# NUC505_v1 register map
File version: 1.0
Registers are 32-bit, read-write, reset 0x0 unless marked. A register's access mark holds for its fields unless they carry their own. Offsets are from the block's base; [hi:lo] are bit positions; {n}, {i} and the like mark numbered series; 'fields as' and 'values as' point back to an identical list.

## PWM — PWM Register Map
Base 0x400E6000
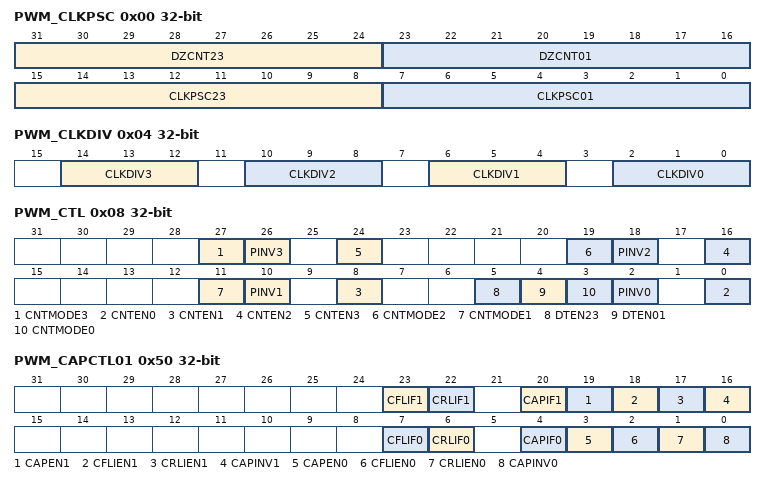
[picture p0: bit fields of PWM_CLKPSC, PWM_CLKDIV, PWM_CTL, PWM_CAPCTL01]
0x00 PWM_CLKPSC — PWM Pre-scale Register
  [31:24] DZCNT23 — Dead-time Interval Register 1. These 8-bit determine Dead-time length.
  [23:16] DZCNT01 — Dead-time Interval Register 0. These 8-bit determine Dead-time length.
  [15:8] CLKPSC23 — Clock Pre-scale 1 for PWM Counter 2 3. Clock input is divided by (CLKPSC23+1) before it is fed to the counter 2 3.
  [7:0] CLKPSC01 — Clock Pre-scale 0 for PWM Counter 0 1. Clock input is divided by (CLKPSC01+1) before it is fed to the counter 0 1.
0x04 PWM_CLKDIV — PWM Clock Select Register
  [14:12] CLKDIV3 — PWM Counter 3 Clock Source Selection. Select clock input for timer 3.
    0=PWM_CLK/2; 1=PWM_CLK/4; 2=PWM_CLK/8; 3=PWM_CLK/16; 4=PWM_CLK/1
  [10:8] CLKDIV2 — PWM Counter 2 Clock Source Selection. Select clock input for PWM Counter 2. (Table is the same as CLKDIV3)
  [6:4] CLKDIV1 — PWM Counter 1 Clock Source Selection. Select clock input for PWM Counter 1. (Table is the same as CLKDIV3)
  [2:0] CLKDIV0 — PWM Counter 0 Clock Source Selection. Select clock input for PWM Counter 0. (Table is the same as CLKDIV3)
0x08 PWM_CTL — PWM Control Register
  [27] CNTMODE3 — PWM Counter 3 Auto-reload Mode/One-shot Mode. Note: If there is a rising transition at this bit, it will cause PWM_PERIOD3 and PWM_CMPDAT3 be cleared.
    0=One-Shot mode; 1=Auto-Reload mode
  [8n+2] PINV{n} (n=0..3) — PWM Counter {n} Inverter ON/OFF
    0=Inverter OFF; 1=Inverter ON
  [8n] CNTEN{n} (n=0..3) — PWM Counter {n} Enable Control
    0=PWM Counter and clock prescaler stops running; 1=PWM Counter and clock prescaler starts running
  [19] CNTMODE2 — PWM Counter 2 Auto-reload Mode/One-shot Mode. Note: If there is a rising transition at this bit, it will cause PWM_PERIOD2 and PWM_CMPDAT2 be cleared.
    0=One-shot mode; 1=Auto-reload mode
  [11] CNTMODE1 — PWM Counter 1 Auto-reload Mode/One-shot Mode. Note: If there is a rising transition at this bit, it will cause PWM_PERIOD1 and PWM_CMPDAT1 be cleared.
    0=One-shot mode; 1=Auto-reload mode
  [5] DTEN23 — Dead-time 1 Generator Enable Control
    0=Dead-time generator stops running; 1=Dead-time generator starts running
  [4] DTEN01 — Dead-time 0 Generator Enable Control
    values as DTEN23
  [3] CNTMODE0 — PWM Counter 0 Auto-reload Mode/One-shot Mode. If there is a rising transition at this bit, it will cause PWM_PERIOD0 and PWM_CMPDAT0 be cleared.
    0=One-shot mode; 1=Auto-reload mode
{0xC+0xC*i} PWM_PERIOD{i} (i=0..3) — PWM Period Register {i}
  [15:0] PERIOD — PWM Period Register. PERIOD determines the PWM period. Note: Any write to PERIOD will take effect in the next PWM cycle.
{0x10+0xC*i} PWM_CMPDAT{i} (i=0..3) — PWM Comparator Register {i}
  [15:0] CMP — PWM Compare Register. CMP determines the PWM output duty ratio. Note: Any write to CMP will take effect in the next PWM cycle.
{0x14+0xC*i} PWM_CNT{i} ro (i=0..3) — PWM Data Register {i}
  [15:0] CNT — PWM Data Register. User can monitor CNT to know current value in 16-bit down counter.
0x40 PWM_INTEN — PWM Interrupt Enable Register
  [3:0] PIEN — PWM Period Interrupt Enable Control. Note: Each bit controls the corresponding PWM channel.
    0=Period interrupt Disabled; 1=Period interrupt Enabled
0x44 PWM_INTSTS — PWM Interrupt Indication Register
  [3:0] PIF — PWM Timer Interrupt Flag. Note1: Each bit controls the corresponding PWM channel. Note2: User can clear each interrupt flag by writing a one to corresponding bit
    0=Interrupt Flag OFF; 1=Interrupt Flag ON
0x50 PWM_CAPCTL01 — Capture Control Register 0
  [23] CFLIF1 — Capture Falling Latch Interrupt Flag. Note: This bit must be cleared by writing 1 to it.
    0=No capture falling latch condition happened; 1=Capture falling latch condition happened, and this flag will be set to high
  [22] CRLIF1 — Capture Rising Latch Interrupt Flag. Note: This bit must be cleared by writing 1 to it.
    0=No capture rising latch condition happened; 1=Capture rising latch condition happened, and this flag will be set to high
  [20] CAPIF1 — Capture 1 Interrupt Indication. Note: If this bit is "1", PWM-counter 1 will not reload when the next capture interrupt occurs. Write "1" to clear.
    0=Interrupt Flag OFF; 1=Interrupt Flag ON
  [19] CAPEN1 — Capture Channel 1 Function Enable Control. Note1: When Enabled, Capture latched the PMW-counter 1 and saved to PWM_RCAPDAT1 (Rising latch) and PWM_FCAPDAT1 (Falling latch). Note2: When Disabled, Capture does not update PWM_RCAPDAT1 and PWM_FCAPDAT1, and disable Channel 1 Interrupt.
    0=Capture function Disabled; 1=Capture function Enabled
  [18] CFLIEN1 — Channel1 Falling Interrupt Enable Control. Note: When Enabled, if Capture detects Channel 1 has falling transition, Capture issues an Interrupt.
    0=Channel1 Falling Interrupt Disabled; 1=Channel1 Falling Interrupt Enabled
  [17] CRLIEN1 — Channel 1 Rising Interrupt Enable Control. Note: When Enabled, if Capture detects Channel 1 has rising transition, Capture issues an Interrupt.
    0=Channel 1 Rising Interrupt Disabled; 1=Channel 1 Rising Interrupt Enabled
  [16] CAPINV1 — Capture 1 Inverter Enable Control
    0=Capture source inverter Disabled; 1=Capture source inverter Enabled
  [7] CFLIF0 — Capture Falling Latch Interrupt Flag. Note: This bit must be cleared by writing 1 to it.
    values as CFLIF1
  [6] CRLIF0 — Capture Rising Latch Interrupt Flag. Note: This bit must be cleared by writing 1 to it.
    values as CRLIF1
  [4] CAPIF0 — Capture 0 Interrupt Indication. Note: If this bit is "1", PWM-counter 0 will not reload when the next capture interrupt occur. Write "1" clear.
    0=Interrupt Flag OFF; 1=Interrupt Flag ON
  [3] CAPEN0 — Capture Channel 0 Function Enable Control. Note1: When Enabled, Capture latched the PWM-counter value and saved to PWM_RCAPDAT0 (Rising latch) and PWM_FCAPDAT0 (Falling latch). Note2: When Disabled, Capture does not update PWM_RCAPDAT0 and PWM_FCAPDAT0, and disable Channel 0 Interrupt.
    0=Capture function Disabled; 1=Capture function Enabled
  [2] CFLIEN0 — Channel 0 Falling Interrupt Enable Control. Note: When Enabled, if Capture detects Channel 0 has falling transition, Capture issues an Interrupt.
    0=Channel 0 Falling Interrupt Disabled; 1=Channel 0 Falling Interrupt Enabled
  [1] CRLIEN0 — Channel 0 Rising Interrupt Enable Control. Note: When Enabled, if Capture detects Channel 0 has rising transition, Capture issues an Interrupt.
    0=Channel 0 Rising Interrupt Enable Disabled; 1=Channel 0 Rising Interrupt Enable Enabled
  [0] CAPINV0 — Capture 0 Inverter Enable Control
    0=Capture source inverter Disabled; 1=Capture source inverter Enabled. Reverse the input signal from GPIO
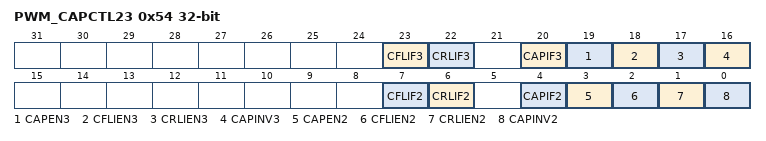
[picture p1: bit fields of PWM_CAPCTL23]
0x54 PWM_CAPCTL23 — Capture Control Register 1
  [23] CFLIF3 — Capture Falling Latch Interrupt Flag. Note: This bit must be cleared by writing 1 to it.
    0=No capture falling latch condition happened; 1=Capture falling latch condition happened, this flag will be set to high
  [22] CRLIF3 — Capture Rising Latch Interrupt Flag. Note: This bit must be cleared by writing 1 to it.
    0=No capture rising latch condition happened; 1=Capture rising latch condition happened, this flag will be set to high
  [20] CAPIF3 — Capture 3 Interrupt Indication. Note: If this bit is "1", PWM-counter 3 will not reload when next capture interrupt occur.
    0=Interrupt Flag OFF; 1=Interrupt Flag ON
  [19] CAPEN3 — Capture Channel 3 Function Enable Control. Note: When Enabled, Capture latched the PMW-counter and saved to PWM_RCAPDAT3 (Rising latch) and PWM_FCAPDAT3 (Falling latch). When Disabled, Capture does not update PWM_RCAPDAT3 and PWM_FCAPDAT3, and disable Channel 3 Interrupt.
    0=Capture function Disabled; 1=Capture function Enabled
  [18] CFLIEN3 — Channel 3 Falling Interrupt Enable Control. Note: When Enabled, if Capture detects Channel 3 has falling transition, Capture issues an Interrupt.
    0=Channel 3 Falling Interrupt Disabled; 1=Channel 3 Falling Interrupt Enabled
  [17] CRLIEN3 — Channel 3 Rising Interrupt Enable Control. Note: When Enabled, if Capture detects Channel 3 has rising transition, Capture issues an Interrupt.
    0=Channel 3 Rising Interrupt Disabled; 1=Channel 3 Rising Interrupt Enabled
  [16] CAPINV3 — Capture 3 Inverter Enable Control
    values as PWM_CAPCTL01.CAPINV0
  [7] CFLIF2 — Capture Falling Latch Interrupt Flag. Note: This bit must be cleared by writing 1 to it.
    values as CFLIF3
  [6] CRLIF2 — Capture Rising Latch Interrupt Flag. Note: This bit must be cleared by writing 1 to it.
    values as CRLIF3
  [4] CAPIF2 — Capture 2 Interrupt Indication. Note: If this bit is "1", PWM-counter 2 will not reload when next capture interrupt occur.
    0=Interrupt Flag OFF; 1=Interrupt Flag ON
  [3] CAPEN2 — Capture Channel 2 Function Enable Control. Note: When Enabled, Capture latched the PMW-counter value and saved to PWM_RCAPDAT2 (Rising latch) and PWM_FCAPDAT2 (Falling latch). When Disabled, Capture does not update PWM_RCAPDAT2 and PWM_FCAPDAT2, and disable Channel 2 Interrupt.
    0=Capture function Disabled; 1=Capture function Enabled
  [2] CFLIEN2 — Channel 2 Falling Interrupt Enable Control. Note: When Enabled, if Capture detects Channel 2 has falling transition, Capture issues an Interrupt.
    0=Channel 2 Falling Interrupt Disabled; 1=Channel 2 Falling Interrupt Enabled
  [1] CRLIEN2 — Channel 2 Rising Interrupt Enable Control. Note: When Enabled, if Capture detects Channel 2 has rising transition, Capture issues an Interrupt.
    0=Channel 2 Rising Interrupt Disabled; 1=Channel 2 Rising Interrupt Enabled
  [0] CAPINV2 — Capture 2 Inverter Enable Control
    values as PWM_CAPCTL01.CAPINV0
{0x58+8i} PWM_RCAPDAT{i} (i=0..3) — Capture Rising Latch Register (Channel {i})
  [15:0] RCAPDAT — Capture Rising Latch Register. Latch the PWM counter when Channel 0/1/2/3 has rising transition.
{0x5C+8i} PWM_FCAPDAT{i} (i=0..3) — Capture Falling Latch Register (Channel {i})
  [15:0] FCAPDAT — Capture Falling Latch Register. Latch the PWM counter when Channel 0/1/2/3 has Falling transition.
0x78 PWM_CAPINEN — Capture Input Enable Register
  [0] CAPINEN — Capture Input Enable Control
    0=PWM Channel capture input path Disabled. The input of PWM channel capture function is always regarded as 0; 1=PWM Channel capture input path Enabled. The input of PWM channel capture function comes from correlative multifunction pin
0x7C PWM_POEN — PWM Output Enable Register
  [3:0] POEN — PWM Counter Output Enable Control. Note: Each bit controls the corresponding PWM channel.
    0=PWM Counter Output Disabled; 1=PWM Counter Output Enabled
